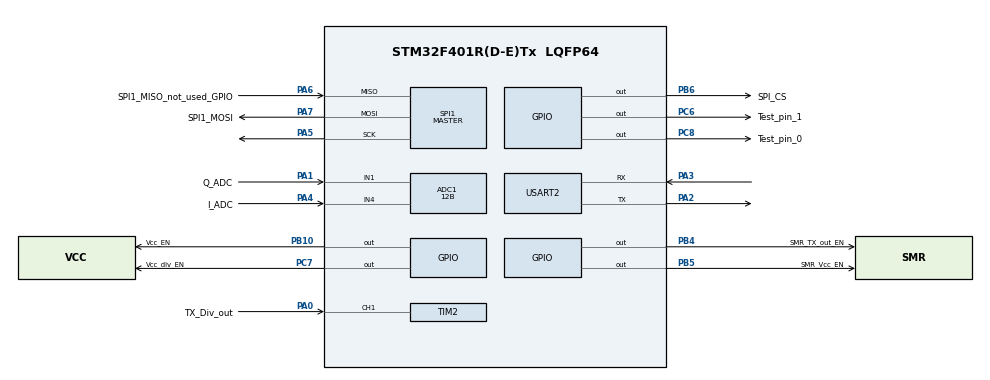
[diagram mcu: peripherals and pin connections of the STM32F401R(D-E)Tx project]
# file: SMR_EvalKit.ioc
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ADC1.Channel-0\#ChannelRegularConversion=ADC_CHANNEL_1
ADC1.Channel-1\#ChannelRegularConversion=ADC_CHANNEL_4
ADC1.Channel-2\#ChannelRegularConversion=ADC_CHANNEL_TEMPSENSOR
ADC1.Channel-3\#ChannelRegularConversion=ADC_CHANNEL_VREFINT
ADC1.ClockPrescaler=ADC_CLOCK_SYNC_PCLK_DIV4
ADC1.ContinuousConvMode=DISABLE
ADC1.DMAContinuousRequests=ENABLE
ADC1.DataAlign=ADC_DATAALIGN_RIGHT
ADC1.DiscontinuousConvMode=DISABLE
ADC1.EOCSelection=ADC_EOC_SEQ_CONV
ADC1.EnableAnalogWatchDog=false
ADC1.ExternalTrigConv=ADC_SOFTWARE_START
ADC1.ExternalTrigConvEdge=ADC_EXTERNALTRIGCONVEDGE_NONE
ADC1.InjNumberOfConversion=0
ADC1.NbrOfConversion=4
ADC1.NbrOfConversionFlag=1
ADC1.Rank-0\#ChannelRegularConversion=1
ADC1.Rank-1\#ChannelRegularConversion=2
ADC1.Rank-2\#ChannelRegularConversion=3
ADC1.Rank-3\#ChannelRegularConversion=4
ADC1.Resolution=ADC_RESOLUTION_12B
ADC1.SamplingTime-0\#ChannelRegularConversion=ADC_SAMPLETIME_56CYCLES
ADC1.SamplingTime-1\#ChannelRegularConversion=ADC_SAMPLETIME_112CYCLES
ADC1.SamplingTime-2\#ChannelRegularConversion=ADC_SAMPLETIME_112CYCLES
ADC1.SamplingTime-3\#ChannelRegularConversion=ADC_SAMPLETIME_112CYCLES
ADC1.ScanConvMode=ENABLE
ADC1.master=1
Dma.ADC1.0.Direction=DMA_PERIPH_TO_MEMORY
Dma.ADC1.0.FIFOMode=DMA_FIFOMODE_DISABLE
Dma.ADC1.0.Instance=DMA2_Stream4
Dma.ADC1.0.MemDataAlignment=DMA_MDATAALIGN_HALFWORD
Dma.ADC1.0.MemInc=DMA_MINC_ENABLE
Dma.ADC1.0.Mode=DMA_CIRCULAR
Dma.ADC1.0.PeriphDataAlignment=DMA_PDATAALIGN_HALFWORD
Dma.ADC1.0.PeriphInc=DMA_PINC_DISABLE
Dma.ADC1.0.Priority=DMA_PRIORITY_HIGH
Dma.Request0=ADC1
Mcu.Family=STM32F4
Mcu.Name=STM32F401R(D-E)Tx
Mcu.Package=LQFP64
NVIC.ADC_IRQn=true\:0\:0\:false\:false\:true
NVIC.DMA2_Stream4_IRQn=true\:0\:0\:false\:false\:true
NVIC.PriorityGroup=NVIC_PRIORITYGROUP_0
NVIC.SPI1_IRQn=true\:0\:0\:false\:false\:true
NVIC.TIM2_IRQn=true\:0\:0\:false\:false\:true
NVIC.TIM4_IRQn=true\:0\:0\:false\:false\:true
NVIC.TIM5_IRQn=true\:0\:0\:false\:false\:true
NVIC.USART2_IRQn=true\:0\:0\:false\:false\:true
PA0-WKUP.GPIO_Label=TX_Div_out
PA0-WKUP.Signal=S_TIM2_CH1_ETR
PA1.GPIO_Label=Q_ADC
PA1.Signal=ADCx_IN1
PA13.GPIO_Label=TMS
PA13.Mode=Trace_Asynchronous_SW
PA13.Signal=SYS_JTMS-SWDIO
PA14.GPIO_Label=TCK
PA14.Mode=Trace_Asynchronous_SW
PA14.Signal=SYS_JTCK-SWCLK
PA2.Mode=Asynchronous
PA2.Signal=USART2_TX
PA3.Mode=Asynchronous
PA3.Signal=USART2_RX
PA4.GPIO_Label=I_ADC
PA4.Signal=ADCx_IN4
PA5.Mode=Full_Duplex_Master
PA5.Signal=SPI1_SCK
PA6.GPIO_Label=SPI1_MISO_not_used_GPIO
PA6.Mode=Full_Duplex_Master
PA6.Signal=SPI1_MISO
PA7.GPIO_Label=SPI1_MOSI
PA7.Mode=Full_Duplex_Master
PA7.Signal=SPI1_MOSI
PB10.GPIO_Label=Vcc_EN
PB10.Signal=GPIO_Output
PB3.GPIO_Label=SWO
PB3.Mode=Trace_Asynchronous_SW
PB3.Signal=SYS_JTDO-SWO
PB4.GPIO_Label=SMR_TX_out_EN
PB4.Signal=GPIO_Output
PB5.GPIO_Label=SMR_Vcc_EN
PB5.Signal=GPIO_Output
PB6.GPIO_Label=SPI_CS
PB6.Signal=GPIO_Output
PC6.GPIO_Label=Test_pin_1
PC6.Signal=GPIO_Output
PC7.GPIO_Label=Vcc_div_EN
PC7.Signal=GPIO_Output
PC8.GPIO_Label=Test_pin_0
PC8.Signal=GPIO_Output
PH0\ -\ OSC_IN.Mode=HSE-External-Clock-Source
PH0\ -\ OSC_IN.Signal=RCC_OSC_IN
PH1\ -\ OSC_OUT.Mode=HSE-External-Clock-Source
PH1\ -\ OSC_OUT.Signal=RCC_OSC_OUT
ProjectManager.HeapSize=0x200
ProjectManager.StackSize=0x400
ProjectManager.TargetToolchain=SW4STM32
RCC.48MHZClocksFreq_Value=48000000
RCC.AHBFreq_Value=84000000
RCC.APB1CLKDivider=RCC_HCLK_DIV2
RCC.APB1Freq_Value=42000000
RCC.APB1TimFreq_Value=84000000
RCC.APB2Freq_Value=84000000
RCC.APB2TimFreq_Value=84000000
RCC.CortexFreq_Value=84000000
RCC.HCLKFreq_Value=84000000
RCC.HSE_VALUE=8000000
RCC.HSI_VALUE=16000000
RCC.LSE_VALUE=32768
RCC.PLLM=8
RCC.PLLN=336
RCC.PLLP=RCC_PLLP_DIV4
RCC.PLLQ=7
RCC.PLLSourceVirtual=RCC_PLLSOURCE_HSE
RCC.SYSCLKFreq_VALUE=84000000
RCC.SYSCLKSource=RCC_SYSCLKSOURCE_PLLCLK
RCC.VCOOutputFreq_Value=336000000
SH.ADCx_IN1.0=ADC1_IN1,IN1
SH.ADCx_IN4.0=ADC1_IN4,IN4
SH.S_TIM2_CH1_ETR.0=TIM2_CH1,Input_Capture1_from_TI1
SPI1.Mode=SPI_MODE_MASTER
TIM2.ICPrescaler-Input_Capture1_from_TI1=TIM_ICPSC_DIV8
TIM2.Period=100000
TIM2.Prescaler=83
TIM4.Period=400
TIM4.Prescaler=83
TIM5.Period=10000
TIM5.Prescaler=83
VP_ADC1_TempSens_Input.Mode=IN-TempSens
VP_ADC1_Vref_Input.Mode=IN-Vrefint
VP_TIM2_VS_ClockSourceINT.Mode=Internal
VP_TIM4_VS_ClockSourceINT.Mode=Internal
VP_TIM5_VS_ClockSourceINT.Mode=Internal
board=NUCLEO-F401RE

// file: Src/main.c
/**
  ******************************************************************************
  * File Name          : main.c
  * Description        : Main program body
  ******************************************************************************
  *
  * COPYRIGHT(c) 2017 STMicroelectronics
  *
  * Redistribution and use in source and binary forms, with or without modification,
  * are permitted provided that the following conditions are met:
  *   1. Redistributions of source code must retain the above copyright notice,
  *      this list of conditions and the following disclaimer.
  *   2. Redistributions in binary form must reproduce the above copyright notice,
  *      this list of conditions and the following disclaimer in the documentation
  *      and/or other materials provided with the distribution.
  *   3. Neither the name of STMicroelectronics nor the names of its contributors
  *      may be used to endorse or promote products derived from this software
  *      without specific prior written permission.
  *
  * THIS SOFTWARE IS PROVIDED BY THE COPYRIGHT HOLDERS AND CONTRIBUTORS "AS IS"
  * AND ANY EXPRESS OR IMPLIED WARRANTIES, INCLUDING, BUT NOT LIMITED TO, THE
  * IMPLIED WARRANTIES OF MERCHANTABILITY AND FITNESS FOR A PARTICULAR PURPOSE ARE
  * DISCLAIMED. IN NO EVENT SHALL THE COPYRIGHT HOLDER OR CONTRIBUTORS BE LIABLE
  * FOR ANY DIRECT, INDIRECT, INCIDENTAL, SPECIAL, EXEMPLARY, OR CONSEQUENTIAL
  * DAMAGES (INCLUDING, BUT NOT LIMITED TO, PROCUREMENT OF SUBSTITUTE GOODS OR
  * SERVICES; LOSS OF USE, DATA, OR PROFITS; OR BUSINESS INTERRUPTION) HOWEVER
  * CAUSED AND ON ANY THEORY OF LIABILITY, WHETHER IN CONTRACT, STRICT LIABILITY,
  * OR TORT (INCLUDING NEGLIGENCE OR OTHERWISE) ARISING IN ANY WAY OUT OF THE USE
  * OF THIS SOFTWARE, EVEN IF ADVISED OF THE POSSIBILITY OF SUCH DAMAGE.
  *
  ******************************************************************************
  */

/* VERSION */
/*-----------FIRMWARE VERSION: 1V1-------------------------------------------*/
/*-------------Data: 10-03-2017 --------------------------------------------*/
#include "main.h"
#include "stm32f4xx_hal.h"

#include "adc.h"
#include "dma.h"
#include "spi.h"
#include "tim.h"
#include "usart.h"
#include "gpio.h"

/* USER CODE BEGIN Includes */
#include "system_clock.h"
#include "CONFIG.h"
#include "Initialization.h"
#include "Framework.h"
#include "Processing.h"
#include "ad5662.h"
/* USER CODE END Includes */

/* USER CODE BEGIN PV */
/* Private variables ---------------------------------------------------------*/

/* USER CODE END PV */

/* USER CODE BEGIN PFP */
/* Private function prototypes -----------------------------------------------*/

/* USER CODE END PFP */

int main(void)
{

  /* MCU Configuration----------------------------------------------------------*/

  /* Reset of all peripherals, Initializes the Flash interface and the Systick. */
  HAL_Init();

  /* Configure the system clock */
  SystemClock_Config();

  /* Initialize all configured peripherals */
  MX_GPIO_Init();			/* GPIOs */
  MX_DMA_Init();			/* read/write values in registers	*/
  MX_ADC1_Init();			/* for capturing and sampling sensor receive signals */
  MX_USART2_UART_Init();	/* for communicating with users */
  MX_SPI1_Init();			/* to send DAC values to set transmit frequency */
  MX_TIM2_Init();			/* timer for measuring down-converted transmit frequency */
  MX_TIM4_Init();			/* system timer: for ADC sampling and FMCW ramp generating and monitor measurement cycle duration */
  MX_TIM5_Init();			/* timer for indicating UART-receive time out */

  /* USER CODE BEGIN 2 */
  /*	initialize the application parameters	*/
  g_InitApplication();

  /*	active SMR module	*/
  HAL_GPIO_WritePin(Vcc_EN_GPIO_Port, Vcc_EN_Pin, GPIO_PIN_SET);	/* supply power to SMR adapter board */
  HAL_Delay(1);	/*	wait 1ms for power up	*/
  g_ActivateSMR(1);/*	switch on the SMR	*/

  /* Start software components */
  if(HAL_ADC_Start_DMA(&hadc1, (uint32_t*)&ADC_DMA_val, NBR_ADC_CHANNEL) != HAL_OK)		/* Start ADC-DMA for reading ADC values */
  {
	  Error_Handler();	/* Error in starting ADC-DMA */
  }

  /* USER CODE END 2 */

  /* Infinite loop */
  while (1)
  {

	g_ActivateCommands();
	g_ExecuteCommands();
  }

}

void Error_Handler(void)
{
  while(1)
  {
  }
}

/************************ (C) COPYRIGHT STMicroelectronics *****END OF FILE****/
